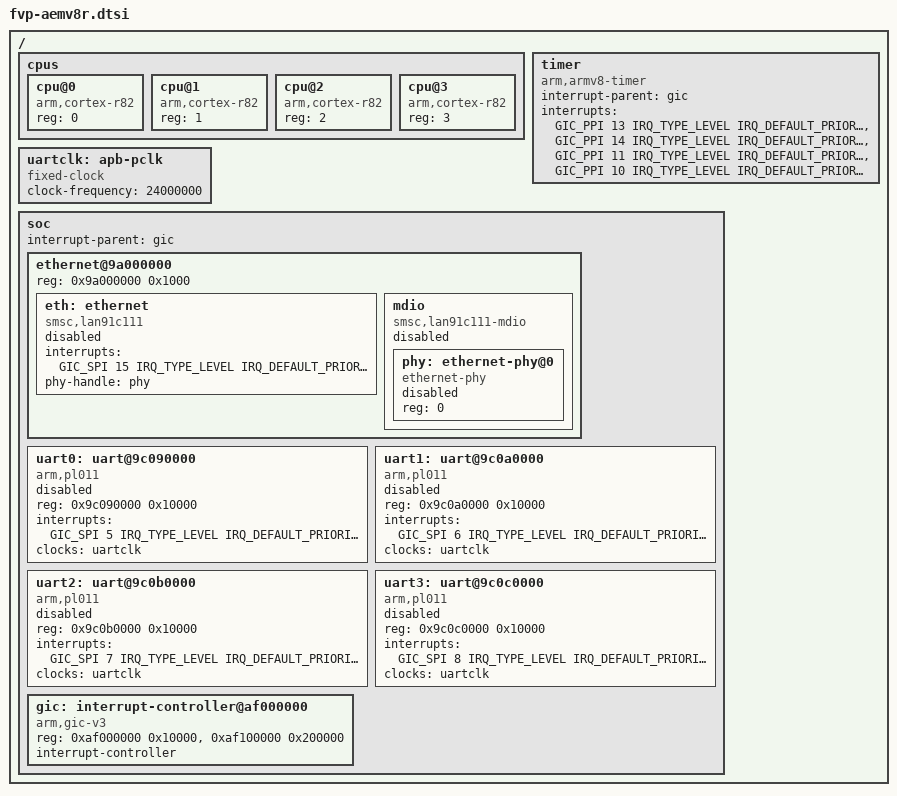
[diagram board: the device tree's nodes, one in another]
/*
 * Copyright (c) 2021 Arm Limited (or its affiliates). All rights reserved.
 * SPDX-License-Identifier: Apache-2.0
 */

#include <mem.h>
#include <arm64/armv8-r.dtsi>
#include <zephyr/dt-bindings/interrupt-controller/arm-gic.h>

/ {
	cpus {
		#address-cells = <1>;
		#size-cells = <0>;

		cpu@0 {
			compatible = "arm,cortex-r82";
			reg = <0>;
			device_type = "cpu";
		};

		cpu@1 {
			compatible = "arm,cortex-r82";
			reg = <1>;
			device_type = "cpu";
		};

		cpu@2 {
			compatible = "arm,cortex-r82";
			reg = <2>;
			device_type = "cpu";
		};

		cpu@3 {
			compatible = "arm,cortex-r82";
			reg = <3>;
			device_type = "cpu";
		};
	};

	timer {
		compatible = "arm,armv8-timer";
		interrupt-parent = <&gic>;
		interrupts = <GIC_PPI 13 IRQ_TYPE_LEVEL
			      IRQ_DEFAULT_PRIORITY>,
			     <GIC_PPI 14 IRQ_TYPE_LEVEL
			      IRQ_DEFAULT_PRIORITY>,
			     <GIC_PPI 11 IRQ_TYPE_LEVEL
			      IRQ_DEFAULT_PRIORITY>,
			     <GIC_PPI 10 IRQ_TYPE_LEVEL
			      IRQ_DEFAULT_PRIORITY>;
	};

	uartclk: apb-pclk {
		compatible = "fixed-clock";
		clock-frequency = <24000000>;
		#clock-cells = <0>;
	};

	soc {
		interrupt-parent = <&gic>;

		ethernet@9a000000 {
			reg = <0x9a000000 0x1000>;

			eth: ethernet {
				compatible = "smsc,lan91c111";
				interrupts = <GIC_SPI 15 IRQ_TYPE_LEVEL IRQ_DEFAULT_PRIORITY>;

				phy-handle = <&phy>;
				status = "disabled";
			};

			mdio: mdio {
				compatible = "smsc,lan91c111-mdio";
				#address-cells = <1>;
				#size-cells = <0>;
				status = "disabled";

				phy: ethernet-phy@0 {
					compatible = "ethernet-phy";
					reg = <0>;
					status = "disabled";
				};
			};
		};

		uart0: uart@9c090000 {
			compatible = "arm,pl011";
			reg = <0x9c090000 0x10000>;
			interrupts = <GIC_SPI 5 IRQ_TYPE_LEVEL IRQ_DEFAULT_PRIORITY>;
			interrupt-names = "irq_5";
			clocks = <&uartclk>;
			status = "disabled";
		};

		uart1: uart@9c0a0000 {
			compatible = "arm,pl011";
			reg = <0x9c0a0000 0x10000>;
			interrupts = <GIC_SPI 6 IRQ_TYPE_LEVEL IRQ_DEFAULT_PRIORITY>;
			interrupt-names = "irq_6";
			clocks = <&uartclk>;
			status = "disabled";
		};

		uart2: uart@9c0b0000 {
			compatible = "arm,pl011";
			reg = <0x9c0b0000 0x10000>;
			interrupts = <GIC_SPI 7 IRQ_TYPE_LEVEL IRQ_DEFAULT_PRIORITY>;
			interrupt-names = "irq_7";
			clocks = <&uartclk>;
			status = "disabled";
		};

		uart3: uart@9c0c0000 {
			compatible = "arm,pl011";
			reg = <0x9c0c0000 0x10000>;
			interrupts = <GIC_SPI 8 IRQ_TYPE_LEVEL IRQ_DEFAULT_PRIORITY>;
			interrupt-names = "irq_8";
			clocks = <&uartclk>;
			status = "disabled";
		};

		gic: interrupt-controller@af000000 {
			compatible = "arm,gic-v3", "arm,gic";
			reg = <0xaf000000 0x10000>,
			      <0xaf100000 0x200000>;
			interrupt-controller;
			#interrupt-cells = <4>;
			status = "okay";
		};
	};
};
